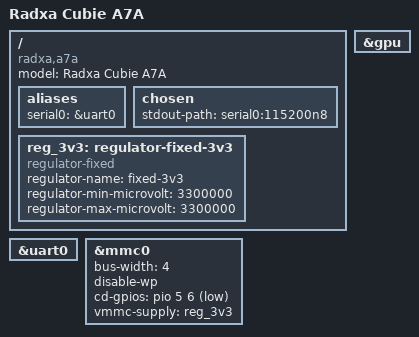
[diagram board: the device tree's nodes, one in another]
// SPDX-License-Identifier: (GPL-2.0-or-later OR MIT)
/*
 * Copyright (C) 2015-2025 Allwinner Technology Co., Ltd.
 * Author: Yao Zi <me@ziyao.cc>
 */

#include "sun60i-a733.dtsi"
#include <dt-bindings/gpio/gpio.h>

/ {
	compatible = "radxa,a7a", "allwinner,a733";
	model = "Radxa Cubie A7A";

	aliases {
		serial0 = &uart0;
	};

	chosen {
		stdout-path = "serial0:115200n8";
	};

	reg_3v3: regulator-fixed-3v3 {
		compatible = "regulator-fixed";
		regulator-name = "fixed-3v3";
		regulator-min-microvolt = <3300000>;
		regulator-max-microvolt = <3300000>;
	};
};

&uart0 {
	status = "okay";
};

&mmc0 {
	/* Missing v(q)mmc-supply which is SWOUT2/CLDO3 of AXP318 */
	bus-width = <4>;
	disable-wp;
	cd-gpios = <&pio 5 6 GPIO_ACTIVE_LOW>;
	vmmc-supply = <&reg_3v3>;
	status = "okay";
};

&gpu {
	status = "okay";
};
